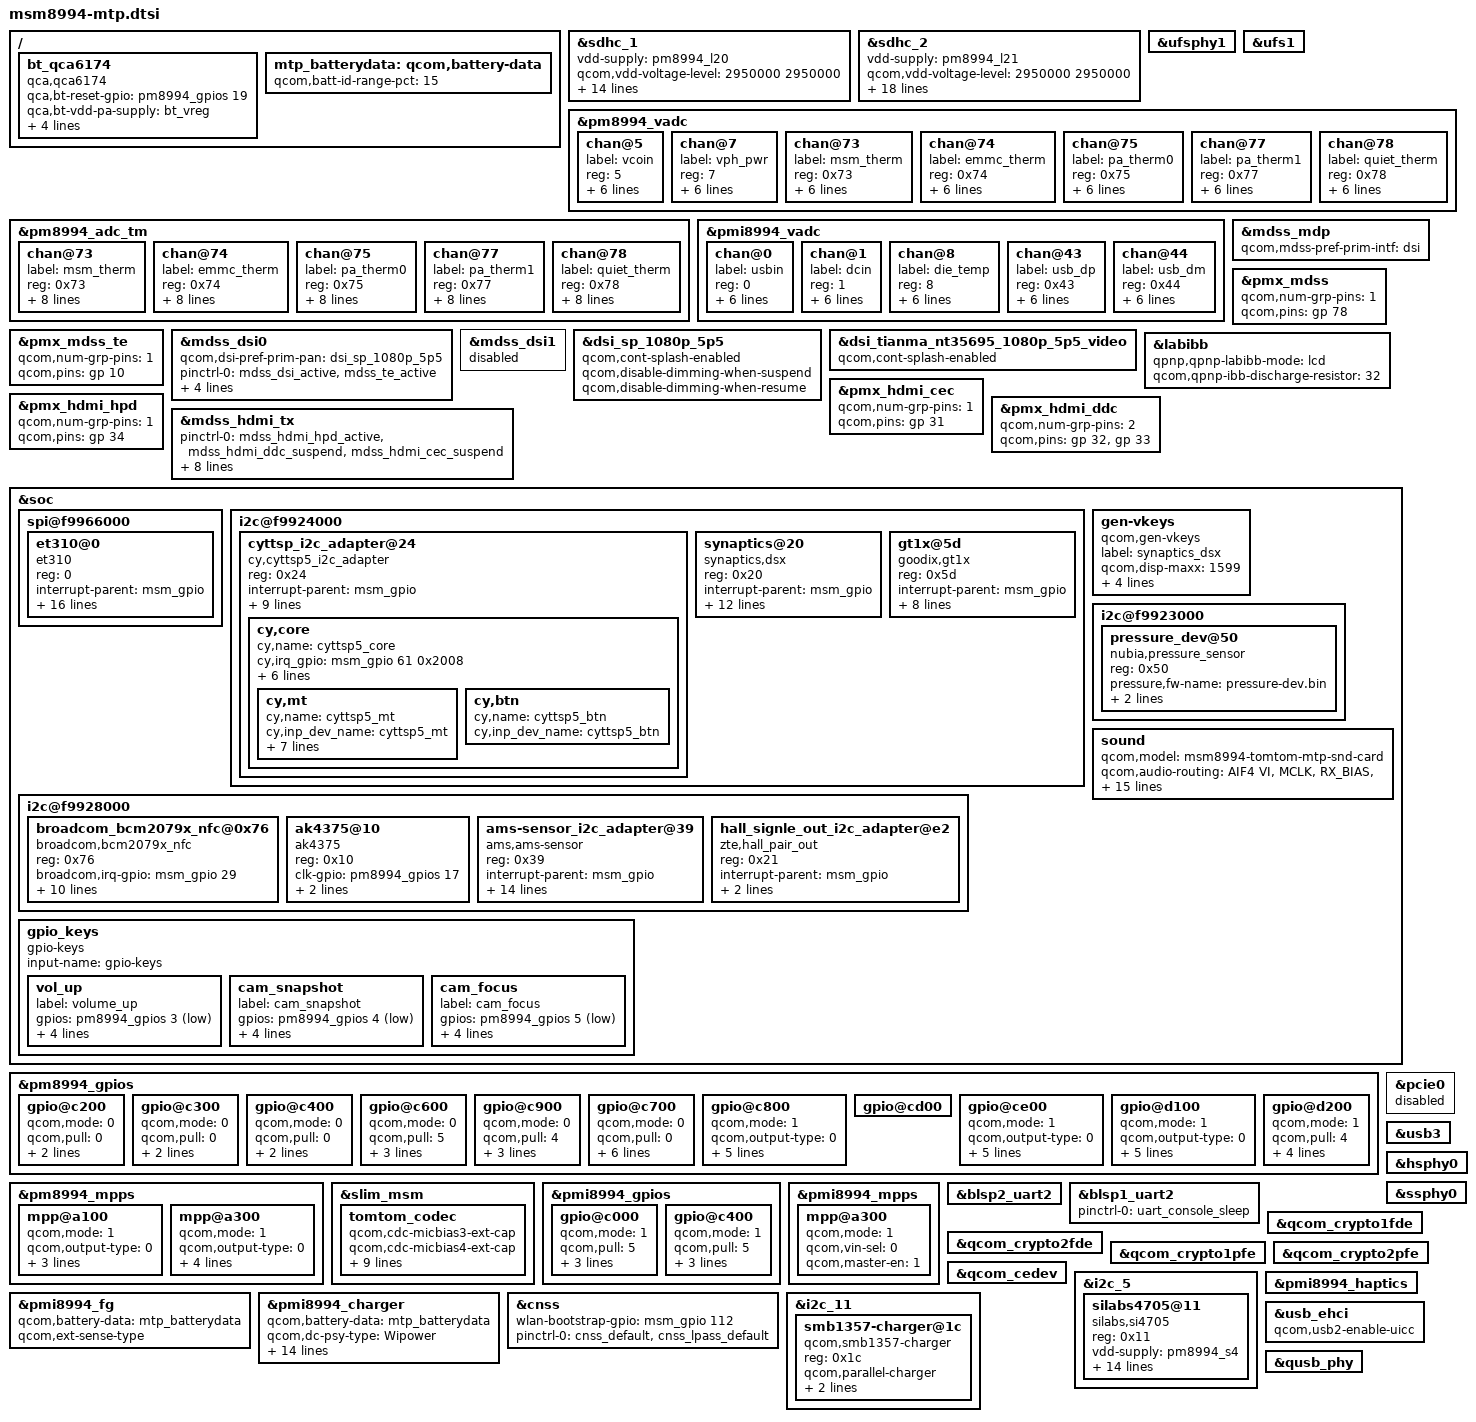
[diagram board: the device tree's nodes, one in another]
/* Copyright (c) 2014-2015, The Linux Foundation. All rights reserved.
 *
 * This program is free software; you can redistribute it and/or modify
 * it under the terms of the GNU General Public License version 2 and
 * only version 2 as published by the Free Software Foundation.
 *
 * This program is distributed in the hope that it will be useful,
 * but WITHOUT ANY WARRANTY; without even the implied warranty of
 * MERCHANTABILITY or FITNESS FOR A PARTICULAR PURPOSE.  See the
 * GNU General Public License for more details.
 */

#include "msm8994-pinctrl.dtsi"
#include "msm8994-camera-sensor-mtp.dtsi"
#include "msm8994-mtp_usb_type_c.dtsi"

/ {
	bt_qca6174 {
		compatible = "qca,qca6174";
		qca,bt-reset-gpio = <&pm8994_gpios 19 0>; /* BT_EN */
		qca,bt-vdd-pa-supply = <&bt_vreg>;
		qca,bt-vdd-io-supply = <&pm8994_s4>;
		qca,bt-vdd-xtal-supply = <&pm8994_l30>;
		qca,bt-vdd-io-voltage-level = <1800000 1800000>;
		qca,bt-vdd-xtal-voltage-level = <1800000 1800000>;
	};
};

&sdhc_1 {
	vdd-supply = <&pm8994_l20>;
	qcom,vdd-voltage-level = <2950000 2950000>;
	qcom,vdd-current-level = <200 570000>;

	vdd-io-supply = <&pm8994_s4>;
	qcom,vdd-io-always-on;
	qcom,vdd-io-voltage-level = <1800000 1800000>;
	qcom,vdd-io-current-level = <200 325000>;

	pinctrl-names = "active", "sleep";
	pinctrl-0 = <&sdc1_clk_on &sdc1_cmd_on &sdc1_data_on &sdc1_rclk_on>;
	pinctrl-1 = <&sdc1_clk_off &sdc1_cmd_off &sdc1_data_off &sdc1_rclk_off>;

	qcom,nonremovable;

	qcom,clk-rates = <400000 20000000 25000000 50000000 100000000 192000000 384000000>;
	qcom,bus-speed-mode = "HS400_1p8v", "HS200_1p8v", "DDR_1p8v";
	status = "ok";
};

&sdhc_2 {
	vdd-supply = <&pm8994_l21>;
	qcom,vdd-voltage-level = <2950000 2950000>;
	qcom,vdd-current-level = <200 800000>;

	vdd-io-supply = <&pm8994_l13>;
	qcom,vdd-io-voltage-level = <1800000 2950000>;
	qcom,vdd-io-current-level = <200 22000>;

	#address-cells = <0>;
	interrupt-parent = <&sdhc_2>;
	interrupts = <0 1 2>;
	#interrupt-cells = <1>;
	interrupt-map-mask = <0xffffffff>;
	interrupt-map = <0 &intc 0 125 0
			1 &intc 0 221 0
			2 &pm8994_gpios 8 0x3>;
	interrupt-names = "hc_irq", "pwr_irq", "status_irq";
	cd-gpios = <&pm8994_gpios 8 0x1>;

	pinctrl-names = "active", "sleep";
	pinctrl-0 = <&sdc2_clk_on &sdc2_cmd_on &sdc2_data_on>;
	pinctrl-1 = <&sdc2_clk_off &sdc2_cmd_off &sdc2_data_off>;

	qcom,clk-rates = <400000 20000000 25000000 50000000 100000000 200000000>;
	qcom,bus-speed-mode = "SDR12", "SDR25", "SDR50", "DDR50", "SDR104";
	status = "ok";
};

&ufsphy1 {
	status = "ok";
};

&ufs1 {
	status = "ok";
};

&pm8994_vadc {
	chan@5 {
		label = "vcoin";
		reg = <5>;
		qcom,decimation = <0>;
		qcom,pre-div-channel-scaling = <1>;
		qcom,calibration-type = "absolute";
		qcom,scale-function = <0>;
		qcom,hw-settle-time = <0>;
		qcom,fast-avg-setup = <0>;
	};

	chan@7 {
		label = "vph_pwr";
		reg = <7>;
		qcom,decimation = <0>;
		qcom,pre-div-channel-scaling = <1>;
		qcom,calibration-type = "absolute";
		qcom,scale-function = <0>;
		qcom,hw-settle-time = <0>;
		qcom,fast-avg-setup = <0>;
	};

	chan@73 {
		label = "msm_therm";
		reg = <0x73>;
		qcom,decimation = <0>;
		qcom,pre-div-channel-scaling = <0>;
		qcom,calibration-type = "ratiometric";
		qcom,scale-function = <2>;
		qcom,hw-settle-time = <2>;
		qcom,fast-avg-setup = <0>;
	};

	chan@74 {
		label = "emmc_therm";
		reg = <0x74>;
		qcom,decimation = <0>;
		qcom,pre-div-channel-scaling = <0>;
		qcom,calibration-type = "ratiometric";
		qcom,scale-function = <2>;
		qcom,hw-settle-time = <2>;
		qcom,fast-avg-setup = <0>;
	};

	chan@75 {
		label = "pa_therm0";
		reg = <0x75>;
		qcom,decimation = <0>;
		qcom,pre-div-channel-scaling = <0>;
		qcom,calibration-type = "ratiometric";
		qcom,scale-function = <2>;
		qcom,hw-settle-time = <2>;
		qcom,fast-avg-setup = <0>;
	};

	chan@77 {
		label = "pa_therm1";
		reg = <0x77>;
		qcom,decimation = <0>;
		qcom,pre-div-channel-scaling = <0>;
		qcom,calibration-type = "ratiometric";
		qcom,scale-function = <2>;
		qcom,hw-settle-time = <2>;
		qcom,fast-avg-setup = <0>;
	};

	chan@78 {
		label = "quiet_therm";
		reg = <0x78>;
		qcom,decimation = <0>;
		qcom,pre-div-channel-scaling = <0>;
		qcom,calibration-type = "ratiometric";
		qcom,scale-function = <2>;
		qcom,hw-settle-time = <2>;
		qcom,fast-avg-setup = <0>;
	};
};

&pm8994_adc_tm {
	chan@73 {
		label = "msm_therm";
		reg = <0x73>;
		qcom,decimation = <0>;
		qcom,pre-div-channel-scaling = <0>;
		qcom,calibration-type = "ratiometric";
		qcom,scale-function = <2>;
		qcom,hw-settle-time = <2>;
		qcom,fast-avg-setup = <0>;
		qcom,btm-channel-number = <0x48>;
		qcom,thermal-node;
	};

	chan@74 {
		label = "emmc_therm";
		reg = <0x74>;
		qcom,decimation = <0>;
		qcom,pre-div-channel-scaling = <0>;
		qcom,calibration-type = "ratiometric";
		qcom,scale-function = <2>;
		qcom,hw-settle-time = <2>;
		qcom,fast-avg-setup = <0>;
		qcom,btm-channel-number = <0x68>;
		qcom,thermal-node;
	};

	chan@75 {
		label = "pa_therm0";
		reg = <0x75>;
		qcom,decimation = <0>;
		qcom,pre-div-channel-scaling = <0>;
		qcom,calibration-type = "ratiometric";
		qcom,scale-function = <2>;
		qcom,hw-settle-time = <2>;
		qcom,fast-avg-setup = <0>;
		qcom,btm-channel-number = <0x70>;
		qcom,thermal-node;
	};

	chan@77 {
		label = "pa_therm1";
		reg = <0x77>;
		qcom,decimation = <0>;
		qcom,pre-div-channel-scaling = <0>;
		qcom,calibration-type = "ratiometric";
		qcom,scale-function = <2>;
		qcom,hw-settle-time = <2>;
		qcom,fast-avg-setup = <0>;
		qcom,btm-channel-number = <0x78>;
		qcom,thermal-node;
	};

	chan@78 {
		label = "quiet_therm";
		reg = <0x78>;
		qcom,decimation = <0>;
		qcom,pre-div-channel-scaling = <0>;
		qcom,calibration-type = "ratiometric";
		qcom,scale-function = <2>;
		qcom,hw-settle-time = <2>;
		qcom,fast-avg-setup = <0>;
		qcom,btm-channel-number = <0x80>;
		qcom,thermal-node;
	};
};

/*CONFIG_ZTEMT_MSM8994_CHARGER*/
&pmi8994_vadc {
	chan@0 {
		label = "usbin";
		reg = <0>;
		qcom,decimation = <0>;
		qcom,pre-div-channel-scaling = <4>;
		qcom,calibration-type = "absolute";
		qcom,scale-function = <0>;
		qcom,hw-settle-time = <0>;
		qcom,fast-avg-setup = <0>;
	};

	chan@1 {
		label = "dcin";
		reg = <1>;
		qcom,decimation = <0>;
		qcom,pre-div-channel-scaling = <4>;
		qcom,calibration-type = "absolute";
		qcom,scale-function = <0>;
		qcom,hw-settle-time = <0>;
		qcom,fast-avg-setup = <0>;
	};

/*CONFIG_ZTEMT_MSM8994_CHARGER*/
	chan@8 {
		label = "die_temp";
		reg = <8>;
		qcom,decimation = <0>;
		qcom,pre-div-channel-scaling = <0>;
		qcom,calibration-type = "absolute";
		qcom,scale-function = <3>;
		qcom,hw-settle-time = <0>;
		qcom,fast-avg-setup = <0>;
	};	

	chan@43 {
		label = "usb_dp";
		reg = <0x43>;
		qcom,decimation = <0>;
		qcom,pre-div-channel-scaling = <1>;
		qcom,calibration-type = "absolute";
		qcom,scale-function = <0>;
		qcom,hw-settle-time = <0>;
		qcom,fast-avg-setup = <0>;
	};

	chan@44 {
		label = "usb_dm";
		reg = <0x44>;
		qcom,decimation = <0>;
		qcom,pre-div-channel-scaling = <1>;
		qcom,calibration-type = "absolute";
		qcom,scale-function = <0>;
		qcom,hw-settle-time = <0>;
		qcom,fast-avg-setup = <0>;
	};
};

/*
#include "../dsi-panel-sharp-dualmipi0-wqxga-video.dtsi"
#include "../dsi-panel-sharp-dualmipi1-wqxga-video.dtsi"
#include "../dsi-panel-jdi-1080p-video.dtsi"
*/

#include "zte-dsi-panel-sharp-r63417-1080p-5p5-cmd.dtsi"

/*
#include "zte-dsi-panel-sharp-r63417-1080p-5p5-video.dtsi"
*/
#include "nubia-tianma-nt35695-1080p-5p5-video.dtsi"

&mdss_mdp {
	qcom,mdss-pref-prim-intf = "dsi";
};

&pmx_mdss {
	qcom,num-grp-pins = <1>;
	qcom,pins = <&gp 78>;
};

&pmx_mdss_te {
	qcom,num-grp-pins = <1>;
	qcom,pins = <&gp 10>;
};

&mdss_dsi0 {
	qcom,dsi-pref-prim-pan = <&dsi_sp_1080p_5p5>;
	pinctrl-names = "mdss_default", "mdss_sleep";
	pinctrl-0 = <&mdss_dsi_active &mdss_te_active>;
	pinctrl-1 = <&mdss_dsi_suspend &mdss_te_suspend>;
	qcom,dsi-panel-bias-vreg;
	qcom,platform-reset-gpio = <&msm_gpio 78 0>;
	qcom,platform-te-gpio = <&msm_gpio 10 0>;
};

&mdss_dsi1 {
	status = "no";
};
&dsi_sp_1080p_5p5 {
	qcom,cont-splash-enabled;
	qcom,disable-dimming-when-suspend;
	qcom,disable-dimming-when-resume;
};

&dsi_tianma_nt35695_1080p_5p5_video{
	qcom,cont-splash-enabled;
};

&labibb {
	status = "ok";
	qpnp,qpnp-labibb-mode = "lcd";
	qcom,qpnp-ibb-discharge-resistor = <32>;
};


&pmx_hdmi_cec {
	qcom,num-grp-pins = <1>;
	qcom,pins = <&gp 31>;
};

&pmx_hdmi_ddc {
	qcom,num-grp-pins = <2>;
	qcom,pins = <&gp 32>, <&gp 33>;
};

&pmx_hdmi_hpd {
	qcom,num-grp-pins = <1>;
	qcom,pins = <&gp 34>;
};

&mdss_hdmi_tx {
	pinctrl-names = "hdmi_hpd_active", "hdmi_ddc_active",
				"hdmi_cec_active", "hdmi_active",
				"hdmi_sleep";
	pinctrl-0 = <&mdss_hdmi_hpd_active &mdss_hdmi_ddc_suspend
						&mdss_hdmi_cec_suspend>;
	pinctrl-1 = <&mdss_hdmi_hpd_active &mdss_hdmi_ddc_active
						&mdss_hdmi_cec_suspend>;
	pinctrl-2 = <&mdss_hdmi_hpd_active &mdss_hdmi_cec_active
						&mdss_hdmi_ddc_suspend>;
	pinctrl-3 = <&mdss_hdmi_hpd_active &mdss_hdmi_ddc_active
						&mdss_hdmi_cec_active>;
	pinctrl-4 = <&mdss_hdmi_hpd_suspend &mdss_hdmi_ddc_suspend
						&mdss_hdmi_cec_suspend>;
};

&soc {
/****ztemt add for MHL spi mode ****/

 spi@f9966000 {
		#if 0
		sii8620@0{
			status = "ok";
			compatible = "sii8620drv";
			reg = <0>;
			interrupt-parent = <&msm_gpio>;
			interrupts = <64 0x3>;
			pinctrl-names = "sii8620_int_active","sii8620_int_suspend";
			pinctrl-0 = <&sii8620_int_active &sii8620_id_active &sii8620_reset_active &sii8620_wake_active>;
			pinctrl-1 = <&sii8620_int_suspend &sii8620_id_suspend &sii8620_reset_active &sii8620_wake_active>;
			sii8620-int-gpio = <&msm_gpio 64 0x00>;
			sii8620-reset-gpio = <&msm_gpio 58 0x00>;
			sii8620-idsel-gpio = <&msm_gpio 16 0x00>;
			sii8620-wake-gpio = <&msm_gpio 12 0x00>;
			vdd_power-supply = <&pm8994_l25>;
			spi-max-frequency = <35000000>;
			qcom,hdmi-tx-map = <&mdss_hdmi_tx>;
		};
		#endif
			   
		#if 1
		et310@0{
			status = "ok";
			compatible = "et310";
			reg = <0>;
			interrupt-parent = <&msm_gpio>;
			interrupts = <66 0x3>;
			vdd-supply = <&pm8994_l17>;
			fp-gpio-rst  = <&msm_gpio 62 0x00>;
			fp-gpio-drdy = <&msm_gpio 1 0x00>;
			fp-gpio-enable = <&msm_gpio 0 0x00>;
			//fp,scroll-enable;
			//fp,getkey-enable;
			pinctrl-names = "fp_active", "fp_suspend", "default", "sleep";
			pinctrl-0 = <&fp_drdy_active &fp_rst_active &fp_enable_active>;
			pinctrl-1 = <&fp_drdy_suspend &fp_rst_suspend &fp_enable_suspend>;
			pinctrl-2 = <&spi_10_active &spi_10_cs10_active>;
			pinctrl-3 = <&spi_10_sleep  &spi_10_cs10_sleep>;
			spi-max-frequency = <12000000>;
			fp,tz-enable;
			qcom,qup-id = <3>;
			clock-names = "iface_clk", "core_clk";
			clocks = <&clock_gcc clk_gcc_blsp2_ahb_clk>,
				<&clock_gcc clk_gcc_blsp2_qup4_spi_apps_clk>;
		};
		#endif
    };  
/*****
    i2c@f9923000 {
        sii8620@72 {
                   status = "ok";
                   compatible = "sii8620drv";
                   reg = <0x72>;
                   interrupt-parent = <&msm_gpio>;
                   interrupts = <64 0x3>;
                   pinctrl-names = "sii8620_int_active","sii8620_int_suspend";
                   pinctrl-0 = <&sii8620_int_active &sii8620_id_active &sii8620_reset_active &sii8620_wake_active>;
                   pinctrl-1 = <&sii8620_int_suspend &sii8620_id_suspend &sii8620_reset_active &sii8620_wake_active>;
                   sii8620-int-gpio = <&msm_gpio 64 0x00>;
                   sii8620-reset-gpio = <&msm_gpio 58 0x00>;
                   sii8620-idsel-gpio = <&msm_gpio 16 0x00>;
                   sii8620-wake-gpio = <&msm_gpio 12 0x00>;
                   vdd_power-supply = <&pm8994_l25>;
                   qcom,hdmi-tx-map = <&mdss_hdmi_tx>;
                };
    };
 *****/
   
	i2c@f9924000 {
		cyttsp_i2c_adapter@24 {
			compatible = "cy,cyttsp5_i2c_adapter";
			reg = <0x24>;
			interrupt-parent = <&msm_gpio>;
			interrupts = <61 0x2>;
			cy,adapter_id = "cyttsp5_i2c_adapter";
			vdd_ana-supply = <&pm8994_l22>;
			vcc_i2c-supply = <&pm8994_s4>;
			vcc_i2c2-supply = <&pm8994_s4>;
			pinctrl-names = "cyttsp5_pin_active", "cyttsp5_pin_suspend";
			pinctrl-0 = <&cyttsp5_irq_active &cyttsp5_rst_active>;
			pinctrl-1 = <&cyttsp5_irq_suspend &cyttsp5_rst_suspend>;
			cy,core {
				cy,name = "cyttsp5_core";
				cy,irq_gpio = <&msm_gpio 61 0x2008>;
				cy,rst_gpio = <&msm_gpio 60 0x0>;
				cy,hid_desc_register = <1>;
				/* CY_CORE_FLAG_WAKE_ON_GESTURE | CY_CORE_FLAG_RESTORE_PARAMETERS */
				cy,flags = <0x05>;
				/* CY_CORE_EWG_NONE */
				cy,easy_wakeup_gesture = <0>;
				cy,btn_keys = <139	/* KEY_MENU */
				          102 /* KEY_HOMEPAGE */
					       158>;	/* KEY_BACK */
				cy,btn_keys-tag = <0>;

				cy,mt {
					cy,name = "cyttsp5_mt";

					cy,inp_dev_name = "cyttsp5_mt";
					cy,flags = <0x00>;
					cy,abs =
						/* ABS_MT_POSITION_X, CY_ABS_MIN_X, CY_ABS_MAX_X, 0, 0 */
						<0x35 0 1080 0 0
						/* ABS_MT_POSITION_Y, CY_ABS_MIN_Y, CY_ABS_MAX_Y, 0, 0 */
						0x36 0 1920 0 0
						/* ABS_MT_PRESSURE, CY_ABS_MIN_P, CY_ABS_MAX_P, 0, 0 */
						0x3a 0 255 0 0
						/* CY_IGNORE_VALUE, CY_ABS_MIN_W, CY_ABS_MAX_W, 0, 0 */
						0xffff 0 255 0 0
						/* ABS_MT_TRACKING_ID, CY_ABS_MIN_T, CY_ABS_MAX_T, 0, 0 */
						0x39 0 15 0 0
						/* ABS_MT_TOUCH_MAJOR, 0, 255, 0, 0 */
						0x30 0 255 0 0
						/* ABS_MT_TOUCH_MINOR, 0, 255, 0, 0 */
						0x31 0 255 0 0
						/* ABS_MT_ORIENTATION, -127, 127, 0, 0 */
						0x34 0xffffff81 127 0 0
						/* ABS_MT_TOOL_TYPE, 0, MT_TOOL_MAX, 0, 0 */
						/* 0x37 0 1 0 0 */
						/* ABS_DISTANCE, 0, 255, 0, 0 */
						0x19 0 255 0 0>;

					cy,vkeys_x = <1080>;
					cy,vkeys_y = <1920>;

					cy,virtual_keys = /* KeyCode CenterX CenterY Width Height */
						/* KEY_BACK */
						<158 1360 90 160 180
						/* KEY_MENU */
						139 1360 270 160 180
						/* KEY_HOMEPAGE */
						172 1360 450 160 180
						/* KEY SEARCH */
						217 1360 630 160 180>;
				};

				cy,btn {
					cy,name = "cyttsp5_btn";

					cy,inp_dev_name = "cyttsp5_btn";
				};
			};
		};
		synaptics@20 {
			compatible = "synaptics,dsx";
			reg = <0x20>;
			interrupt-parent = <&msm_gpio>;
			interrupts = <61 0x2008>;
			vdd-supply = <&pm8994_l14>;
			avdd-supply = <&pm8994_l22>;
			pinctrl-names = "pmx_ts_active", "pmx_ts_suspend";
			pinctrl-0 = <&ts_active>;
			pinctrl-1 = <&ts_suspend>;
			synaptics,display-coords = <0 0 1599 2559>;
			synaptics,panel-coords = <0 0 1599 2703>;
			synaptics,reset-gpio = <&msm_gpio 60 0x00>;
			synaptics,irq-gpio = <&msm_gpio 61 0x2008>;
			synaptics,disable-gpios;
			/* Underlying clocks used by secure touch */
			clock-names = "iface_clk", "core_clk";
			clocks = <&clock_gcc clk_gcc_blsp1_ahb_clk>,
				 <&clock_gcc clk_gcc_blsp1_qup2_i2c_apps_clk>;
		};
		gt1x@5d {
			compatible = "goodix,gt1x";
			reg = <0x5d>;
			interrupt-parent = <&msm_gpio>;
			interrupts = <61 0x2008>;
			vdd_ana-supply = <&pm8994_l22>;
			vcc_i2c-supply = <&pm8994_l14>;
			vcc_i2c2-supply = <&pm8994_s4>;
			pinctrl-names = "gt91x_int_default","gt91x_int_sleep";
			pinctrl-0 = <&gt91x_int_default>;
			pinctrl-1 = <&gt91x_int_sleep>;
			goodix,reset-gpio = <&msm_gpio 60 0x00>;
			goodix,irq-gpio = <&msm_gpio 61 0x2008>;
		};
	};

	gen-vkeys {
		compatible = "qcom,gen-vkeys";
		label = "synaptics_dsx";
		qcom,disp-maxx = <1599>;
		qcom,disp-maxy = <2559>;
		qcom,panel-maxx = <1599>;
		qcom,panel-maxy = <2703>;
		qcom,key-codes = <158 139 102 217>;
	};

	i2c@f9928000 { /* BLSP1 QUP6 */
		status = "ok";
/*
		nfc-nci@e {
			compatible = "qcom,nfc-nci";
			reg = <0x0e>;
			qcom,irq-gpio = <&msm_gpio 29 0x00>;
			qcom,dis-gpio = <&msm_gpio 30 0x00>;
			qcom,clk-src = "BBCLK2";
			interrupt-parent = <&msm_gpio>;
			interrupts = <29 0>;
			interrupt-names = "nfc_irq";
			pinctrl-names = "nfc_active","nfc_suspend";
			pinctrl-0 = <&nfc_int_active &nfc_disable_active>;
			pinctrl-1 = <&nfc_int_suspend &nfc_disable_suspend>;
			qcom,clk-gpio = <&pm8994_gpios 10 0>;
			qcom,pwr-req-gpio = <&pm8994_gpios 7 0>;
			clocks = <&clock_rpm clk_bb_clk2_pin>;
			clock-names = "ref_clk";
		};
*/
		broadcom_bcm2079x_nfc@0x76 {
			compatible = "broadcom,bcm2079x_nfc";
			reg = <0x76>;
			broadcom,irq-gpio = <&msm_gpio 29 0x00>;
			broadcom,en-gpio = <&msm_gpio 26 0x00>;
			broadcom,wake-gpio = <&msm_gpio 30 0x00>;
			interrupt-parent = <&msm_gpio>;
			interrupts = <29 0>;
			interrupt-names = "BRCM_NFC_INT";
			pinctrl-names = "bcm2079x_pin_active","bcm2079x_pin_suspend";
			pinctrl-0 = <&bcm2079x_int_active &bcm2079x_en_active &bcm2079x_ctl_active>;
			pinctrl-1 = <&bcm2079x_int_suspend &bcm2079x_en_suspend &bcm2079x_ctl_suspend>;	
			broadcom,clk-gpio = <&pm8994_gpios 10 0>;
			clocks = <&clock_rpm clk_bb_clk2_pin>;
			clock-names = "ref_clk";
		};

               ak4375@10{
                       compatible = "ak4375";
                       reg = <0x10>;
                       clk-gpio = <&pm8994_gpios 17 0x00>;
                       en-gpio = <&msm_gpio 63 0x00>;
                       handset-gpio = <&msm_gpio 9 0x00>;

               };
		// add by ztemt start
		// add the als/prox/gesture sensor and IR-remote control
	    	ams-sensor_i2c_adapter@39 {
                status = "okay";
                reg = <0x39>;
                compatible = "ams,ams-sensor";
                interrupt-parent = <&msm_gpio>;
                interrupts = <40 0>;
                ams,irq-gpio = <&msm_gpio 40 0x00>;
                ams,light-percent = <150>;
	            vdd-supply = <&pm8994_l18>;
	            vio-supply = <&pm8994_s4>;

				pinctrl-names = "als_prox_int_active","als_prox_int_suspend";
				pinctrl-0 = <&als_prox_int_active>;
				pinctrl-1 = <&als_prox_int_suspend>;

                //for tmg3993
                ams,prox-offset-cal-ability-tmg399x = <15>;
                ams,prox-led-plus-cnt-tmg399x = <4>;
                ams,gesture-offset-cal-ability-tmg399x = <40>;
                ams,gesture-led-plus-cnt-tmg399x = <4>;

                //for tmd2772
                ams,prox-offset-cal-ability-tmd2772 = <8>;
                ams,prox-led-plus-cnt-tmd2772 = <12>;

                ams,prox-spy-enable;
                //ams,prox-auto-calibrate;
        };


		hall_signle_out_i2c_adapter@e2 {
			    status = "okay";
			    reg = <0x21>;
			    compatible = "zte,hall_pair_out";
			    interrupt-parent = <&msm_gpio>;
			    hall_device,s-irq-gpio = <&msm_gpio 41 0x00>;
			    hall_device,n-irq-gpio = <&msm_gpio 108 0x00>;
		};
		// add by ztemt end
	};
	i2c@f9923000 {
		status = "ok";
		pressure_dev@50 {
				status = "okay";
				reg = <0x50>;
				compatible = "nubia,pressure_sensor";
				pressure,fw-name = "pressure-dev.bin";
        interrupt-parent = <&msm_gpio>;
				pressure,reset-pin = <&msm_gpio 88 0x00>;
		};

	};

	gpio_keys {
		compatible = "gpio-keys";
		input-name = "gpio-keys";

		vol_up {
			label = "volume_up";
			gpios = <&pm8994_gpios 3 0x1>;
			linux,input-type = <1>;
			linux,code = <115>;
			gpio-key,wakeup;
			debounce-interval = <15>;
		};

		cam_snapshot {
			label = "cam_snapshot";
			gpios = <&pm8994_gpios 4 0x1>;
			linux,input-type = <1>;
			linux,code = <766>;
			gpio-key,wakeup;
			debounce-interval = <15>;
		};

		cam_focus {
			label = "cam_focus";
			gpios = <&pm8994_gpios 5 0x1>;
			linux,input-type = <1>;
			linux,code = <528>;
			gpio-key,wakeup;
			debounce-interval = <15>;
		};


	};

	sound {
		qcom,model = "msm8994-tomtom-mtp-snd-card";

		qcom,audio-routing =
			"AIF4 VI", "MCLK",
			"RX_BIAS", "MCLK",
			"LDO_H", "MCLK",
			"MADINPUT", "MCLK",
			"ultrasound amp", "LINEOUT1",
			"ultrasound amp", "LINEOUT3",
			"AMIC2", "MIC BIAS2 External",
			"MIC BIAS2 External", "Headset Mic",
                     "AMIC3", "MIC BIAS3 External",
                     "MIC BIAS3 External", "Handset Mic",
			"AMIC4", "MIC BIAS4 External",
                     "MIC BIAS4 External", "Sub Handset Mic";


		qcom,us-euro-gpios = <&pm8994_mpps 2 0>;
		qcom,cdc-micbias2-headset-only;
		qcom,mbhc-audio-jack-type = "4-pole-jack";
		qcom,ext-ult-spk-amp-gpio = <&pmi8994_gpios 1 0>;
		qcom,hdmi-audio-rx;
		asoc-codec = <&stub_codec>, <&hdmi_audio>;
		asoc-codec-names = "msm-stub-codec.1", "msm-hdmi-audio-codec-rx";
	};
};

&pm8994_gpios {
	gpio@c200 { /* GPIO 3 */
		qcom,mode = <0>;
		qcom,pull = <0>;
		qcom,vin-sel = <2>;
		qcom,src-sel = <0>;
		status = "okay";
	};

	gpio@c300 { /* GPIO 4 */
		qcom,mode = <0>;
		qcom,pull = <0>;
		qcom,vin-sel = <2>;
		qcom,src-sel = <0>;
		status = "okay";
	};

	gpio@c400 { /* GPIO 5 */
		qcom,mode = <0>;
		qcom,pull = <0>;
		qcom,vin-sel = <2>;
		qcom,src-sel = <0>;
		status = "okay";
	};

	gpio@c600 { /* GPIO 7 */
		/* NFC pwr request */
		qcom,mode = <0>;                /* QPNP_PIN_MODE_DIG_IN */
		qcom,pull = <5>;                /* QPNP_PIN_PULL_NO */
		qcom,vin-sel = <2>;             /* QPNP_PIN_VIN2 */
		qcom,src-sel = <2>;             /* QPNP_PIN_SEL_FUNC_1 */
		qcom,master-en = <1>;
		status = "okay";
	};

	gpio@c900 { /* GPIO 10 */
		/* NFC clk request */
		qcom,mode = <0>;                /* QPNP_PIN_MODE_DIG_IN */
		//qcom,pull = <5>;                /* QPNP_PIN_PULL_NO */
		qcom,pull = <4>;                /* CHANGED by chendongsheng for set QPNP_PIN_PULL_DOWN */
		qcom,vin-sel = <2>;             /* QPNP_PIN_VIN2 */
		qcom,src-sel = <2>;             /* QPNP_PIN_SEL_FUNC_1 */
		qcom,master-en = <1>;
		status = "okay";
	};

	gpio@c700 { /* GPIO 8 */
		qcom,mode = <0>;                /* Digital in */
		qcom,pull = <0>;                /* PULL up 30uA */
		qcom,output-type = <0>;         /* CMOS logic */
		qcom,invert = <0>;              /* Output high */
		qcom,vin-sel = <2>;             /* Logical 1 voltage value 1.8v */
		qcom,src-sel = <0>;             /* Constant */
		qcom,out-strength = <1>;        /* Low drive strength */
		qcom,master-en = <1>;           /* Enable GPIO */
		status = "okay";
	};

	gpio@c800 { /* GPIO 9 */
		qcom,mode = <1>;		/* Digital output */
		qcom,output-type = <0>;		/* CMOS logic */
		qcom,invert = <1>;		/* Output high */
		qcom,vin-sel = <0>;		/* VPH_PWR */
		qcom,src-sel = <0>;		/* Constant */
		qcom,out-strength = <1>;	/* High drive strength */
		qcom,master-en = <1>;		/* Enable GPIO */
		status = "okay";
	};

	gpio@cd00 { /* GPIO 14 */
		status = "okay";
	};

	gpio@ce00 { /* GPIO 15 */
		qcom,mode = <1>;
		qcom,output-type = <0>;
		qcom,pull = <5>;
		qcom,vin-sel = <2>;
		qcom,out-strength = <1>;
		qcom,src-sel = <2>;
		qcom,master-en = <1>;
		status = "okay";
	};

	gpio@d100 { /* GPIO 18 */
		qcom,mode = <1>;		/* Digital output */
		qcom,output-type = <0>;		/* CMOS logic */
		qcom,invert = <0>;		/* Output low initially */
		qcom,vin-sel = <2>;		/* VIN 2 */
		qcom,src-sel = <3>;		/* Function 2 */
		qcom,out-strength = <2>;	/* Medium */
		qcom,master-en = <1>;		/* Enable GPIO */
		status = "okay";
	};

	gpio@d200 { /* GPIO 19 */
		qcom,mode = <1>;         /* Digital output*/
		qcom,pull = <4>;         /* Pulldown 10uA */
		qcom,vin-sel = <2>;      /* VIN2 */
		qcom,src-sel = <0>;      /* GPIO */
		qcom,invert = <0>;       /* Invert */
		qcom,master-en = <1>;    /* Enable GPIO */
		status = "okay";
	};
};

&pm8994_mpps {
	mpp@a100 { /* MPP 2 */
		qcom,mode = <1>;		/* Digital output */
		qcom,output-type = <0>;		/* CMOS logic */
		qcom,vin-sel = <2>;		/* S4 1.8V */
		qcom,src-sel = <0>;		/* Constant */
		qcom,master-en = <1>;		/* Enable GPIO */
		status = "okay";
	};

	mpp@a300 { /* MPP 4 */
		/* HDMI_5v_vreg regulator enable */
		qcom,mode = <1>;		/* Digital output */
		qcom,output-type = <0>;		/* CMOS logic */
		qcom,vin-sel = <2>;		/* S4 1.8V */
		qcom,src-sel = <0>;		/* Constant */
		qcom,master-en = <1>;		/* Enable GPIO */
		qcom,invert = <0>;
		status = "okay";
	};
};

&slim_msm {
	tomtom_codec {
		qcom,cdc-micbias3-ext-cap;
		qcom,cdc-micbias4-ext-cap;
		cdc-vdd-spkdrv-supply = <&pmi8994_boost_pin_ctrl>;
		qcom,cdc-vdd-spkdrv-voltage = <5000000 5000000>;
		qcom,cdc-vdd-spkdrv-current = <600000>;

		cdc-vdd-spkdrv-2-supply = <&pmi8994_boost_pin_ctrl>;
		qcom,cdc-vdd-spkdrv-2-voltage = <5000000 5000000>;
		qcom,cdc-vdd-spkdrv-2-current = <600000>;

		qcom,cdc-on-demand-supplies = "cdc-vdd-spkdrv",
					      "cdc-vdd-spkdrv-2";
	};
};

&pmi8994_gpios {
	gpio@c000 {	/* GPIO 1  Ultrasound PA EN */
		qcom,mode = <1>;	/* DIGITAL OUT */
		qcom,pull = <5>;	/* No Pull */
		qcom,vin-sel = <2>;	/* 1.8 */
		qcom,src-sel = <0>;	/* CONSTANT */
		qcom,master-en = <1>;	/* ENABLE GPIO */
		status = "okay";
	};

	gpio@c400 {	/* GPIO 5  OTG SWITCH EN */
		qcom,mode = <1>;	/* DIGITAL OUT */
		qcom,pull = <5>;	/* No Pull */
		qcom,vin-sel = <2>;	/* 1.8 */
		qcom,src-sel = <0>;	/* GPIO */
		qcom,master-en = <1>;	/* ENABLE GPIO */
		status = "okay";
	};
};

&pmi8994_mpps {
	mpp@a300 { /* MPP 4 */
		/* WLED FET */
		qcom,mode = <1>;	/* DIGITAL OUT */
		qcom,vin-sel = <0>;	/* VIN0 */
		qcom,master-en = <1>;
		status = "okay";
	};
};

&blsp2_uart2 {
	status = "ok";
};

&blsp1_uart2 {
	status= "ok";
	 pinctrl-names = "default";
	 pinctrl-0 = <&uart_console_sleep>;
};

&pcie0 {
	status = "disabled";
};

&usb3 {
	status = "ok";
};

&hsphy0 {
	status = "ok";
};

&ssphy0 {
	status = "ok";
};

&qcom_crypto1fde {
	status = "okay";
};

&qcom_crypto2fde {
	status = "okay";
};

&qcom_crypto1pfe {
	status = "okay";
};

&qcom_crypto2pfe {
	status = "okay";
};

&qcom_cedev {
	status = "okay";
};

&i2c_5 {
	silabs4705@11 { /* SiLabs FM chip, slave id 0x11*/
		status = "ok";
		compatible = "silabs,si4705";
		reg = <0x11>;
		vdd-supply = <&pm8994_s4>;
		silabs,vdd-supply-voltage = <1800000 1800000>;
		va-supply = <&bt_vreg>;
		silabs,va-supply-voltage = <3300000 3300000>;
		pinctrl-names = "pmx_fm_active","pmx_fm_suspend";
		pinctrl-0 = <&fm_int_active &fm_status_int_active &fm_rst_active>;
		pinctrl-1 = <&fm_int_suspend &fm_status_int_suspend &fm_rst_suspend>;
		silabs,reset-gpio = <&msm_gpio 62 0>;
		silabs,int-gpio = <&msm_gpio 9 0>;
		silabs,status-gpio = <&msm_gpio 11 0>;
		#address-cells = <0>;
		interrupts = <0 1>;
		#interrupt-cells = <1>;
		interrupt-map-mask = <0xffffffff>;
		interrupt-map = <
				  0 &msm_gpio 9 2
				  1 &msm_gpio 11 1
				>;
		interrupt-names = "silabs_fm_int", "silabs_fm_status_int";
	};
};
/*CONFIG_ZTEMT_MSM8994_FUEL_GAUGE*/
/{
	mtp_batterydata: qcom,battery-data {
		qcom,batt-id-range-pct = <15>;
		#include "../batterydata-itech-3000mah.dtsi"
   #include "batterydata-ztemt-4v4-2850mah.dtsi"
   #include "batterydata-ztemt-4v4-3000mah.dtsi"
	};
};

&pmi8994_fg {
	qcom,battery-data = <&mtp_batterydata>;
	qcom,ext-sense-type;
};

&pmi8994_haptics {
	status = "okay";
};
/*CONFIG_ZTEMT_MSM8994_CHARGER*/
&pmi8994_charger {
	/*ZTEMT Add*/
	qcom,battery-data = <&mtp_batterydata>;
	qcom,dc-psy-type = "Wipower";
	qcom,dcin-vadc = <&pmi8994_vadc>;
	qcom,wipower-default-ilim-map = <4000000 20000000 550 700 300>;
	qcom,wipower-pt-ilim-map = <4000000 7140000 550 700 300>,
					<7140000 8140000 550 700 300>,
					<8140000 9140000 500 700 300>,
					<9140000 9950000 500 700 300>;
	qcom,wipower-div2-ilim-map = <4000000 4820000 550 700 300>,
					<4820000 5820000 550 700 300>,
					<5820000 6820000 550 650 650>,
					<6820000 7820000 550 700 600>,
					<7820000 8500000 550 700 550>;
};

&cnss {
	wlan-bootstrap-gpio = <&msm_gpio 112 0>;
	pinctrl-names = "default";
	pinctrl-0 = <&cnss_default &cnss_lpass_default>;
};

&i2c_11 {
	smb1357-charger@1c {
		compatible = "qcom,smb1357-charger";
		reg = <0x1c>;
		qcom,parallel-charger;
		qcom,float-voltage-mv = <4400>;
		qcom,recharge-thresh-mv = <100>;
	};
};

&usb_ehci {
	status = "ok";
	qcom,usb2-enable-uicc;
};

&qusb_phy {
	status = "ok";
};
